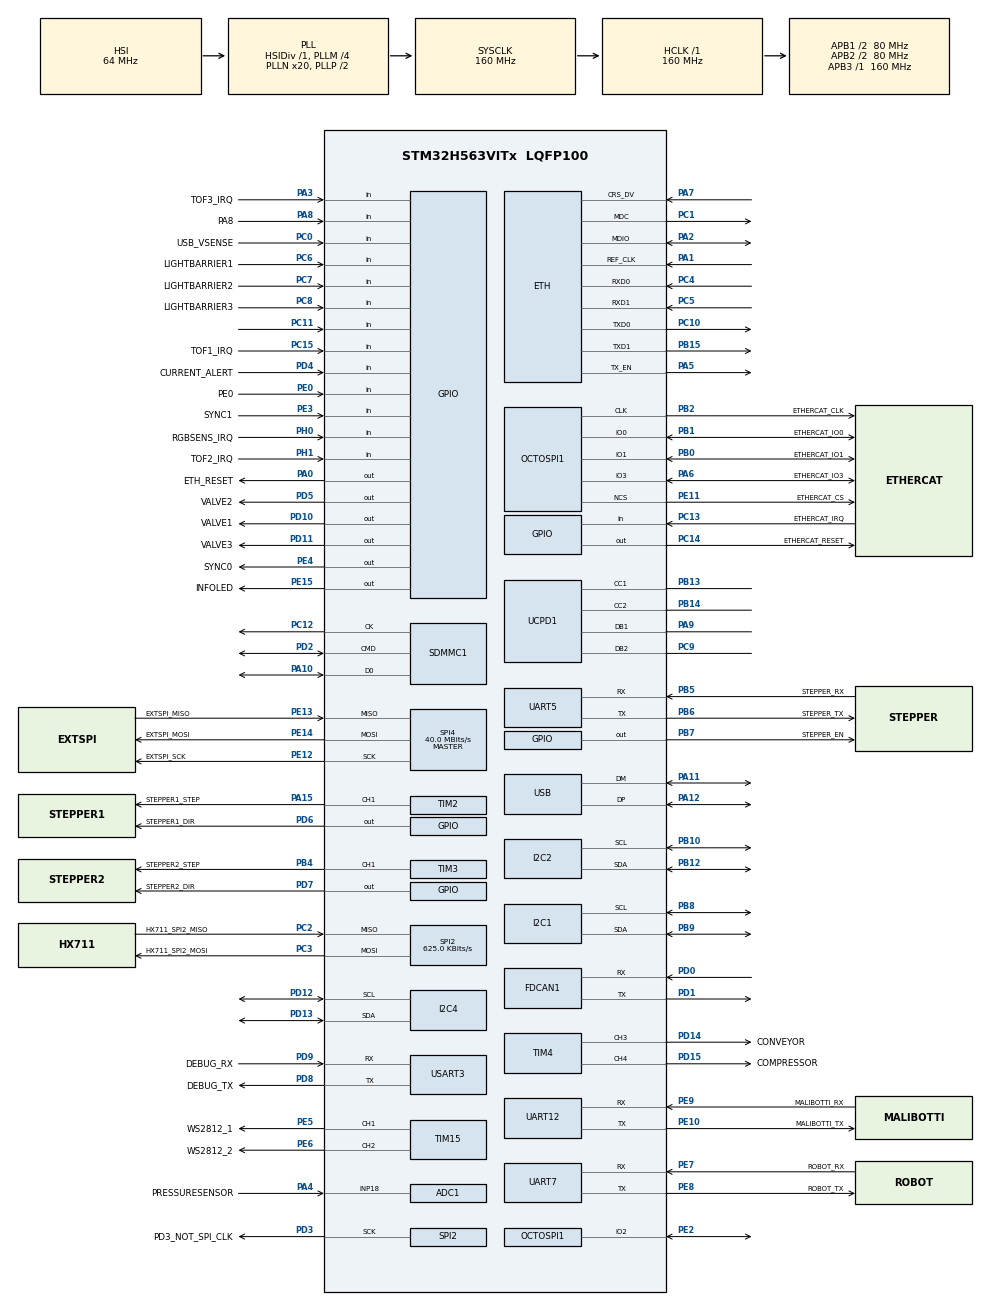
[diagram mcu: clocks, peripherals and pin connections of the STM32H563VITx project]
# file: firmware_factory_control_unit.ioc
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ADC1.Channel-0\#ChannelRegularConversion=ADC_CHANNEL_18
ADC1.ContinuousConvMode=ENABLE
ADC1.MonitoredBy-0\#ChannelRegularConversion=__NULL
ADC1.NbrOfConversionFlag=1
ADC1.OffsetNumber-0\#ChannelRegularConversion=ADC_OFFSET_NONE
ADC1.Rank-0\#ChannelRegularConversion=1
ADC1.SamplingTime-0\#ChannelRegularConversion=ADC_SAMPLETIME_2CYCLES_5
ADC1.master=1
BOOTPATH.BootPathName=LEGACY
BOOTPATH.UserSelectedBootPath=LEGACY
CORTEX_M33_NS.userName=CORTEX_M33
ETH.MediaInterface=HAL_ETH_RMII_MODE
FDCAN1.CalculateBaudRateNominal=1666666
FDCAN1.CalculateTimeBitNominal=600
FDCAN1.CalculateTimeQuantumNominal=200.0
GPDMA1.ChannelPRIV_GPDMACH0=DMA_CHANNEL_NPRIV
GPDMA1.ChannelPRIV_GPDMACH1=DMA_CHANNEL_NPRIV
GPDMA1.DESTINC_GPDMACH1=DMA_DINC_INCREMENTED
GPDMA1.DIRECTION_GPDMACH0=DMA_MEMORY_TO_PERIPH
GPDMA1.DIRECTION_GPDMACH2=DMA_MEMORY_TO_PERIPH
GPDMA1.IPHANDLE_GPDMACH0-SIMPLEREQUEST_GPDMACH0=__NULL
GPDMA1.IPHANDLE_GPDMACH1-SIMPLEREQUEST_GPDMACH1=__NULL
GPDMA1.IPHANDLE_GPDMACH2-SIMPLEREQUEST_GPDMACH2=__NULL
GPDMA1.IPHANDLE_GPDMACH3-SIMPLEREQUEST_GPDMACH3=__NULL
GPDMA1.REQUEST_GPDMACH0=GPDMA1_REQUEST_SPI2_TX
GPDMA1.REQUEST_GPDMACH1=GPDMA1_REQUEST_SPI2_RX
GPDMA1.REQUEST_GPDMACH2=GPDMA1_REQUEST_TIM15_CH1
GPDMA1.REQUEST_GPDMACH3=GPDMA1_REQUEST_TIM15_UP
GPDMA1.SRCINC_GPDMACH0=DMA_SINC_INCREMENTED
GPDMA1.SRCINC_GPDMACH2=DMA_SINC_INCREMENTED
GPDMA1.SRCINC_GPDMACH3=DMA_SINC_INCREMENTED
I2C1.Timing=0x10909CEC
I2C2.Timing=0x10909CEC
I2C4.Timing=0x30909DEC
Mcu.Family=STM32H5
Mcu.Name=STM32H563VITx
Mcu.Package=LQFP100
NVIC.ETH_IRQn=true\:5\:0\:true\:false\:true\:true\:true\:true
NVIC.ETH_WKUP_IRQn=true\:5\:0\:true\:false\:true\:true\:true\:true
NVIC.GPDMA1_Channel0_IRQn=true\:0\:0\:false\:false\:true\:false\:true\:true
NVIC.GPDMA1_Channel1_IRQn=true\:0\:0\:false\:false\:true\:false\:true\:true
NVIC.GPDMA1_Channel2_IRQn=true\:0\:0\:false\:false\:true\:false\:true\:true
NVIC.GPDMA1_Channel3_IRQn=true\:0\:0\:false\:false\:true\:false\:true\:true
NVIC.PriorityGroup=NVIC_PRIORITYGROUP_4
NVIC.SDMMC1_IRQn=true\:0\:0\:false\:false\:true\:true\:true\:true
NVIC.SPI2_IRQn=true\:5\:0\:true\:false\:true\:true\:true\:true
NVIC.UART5_IRQn=true\:5\:0\:true\:false\:true\:true\:true\:true
PA0.GPIO_Label=ETH_RESET
PA0.Signal=GPIO_Output
PA1.Mode=RMII
PA1.Signal=ETH_REF_CLK
PA10.Mode=SD_1_bit
PA10.Signal=SDMMC1_D0
PA11.Mode=Device
PA11.Signal=USB_DM
PA12.Mode=Device
PA12.Signal=USB_DP
PA13(JTMS/SWDIO).Mode=Serial_Wire
PA13(JTMS/SWDIO).Signal=DEBUG_JTMS-SWDIO
PA14(JTCK/SWCLK).Mode=Serial_Wire
PA14(JTCK/SWCLK).Signal=DEBUG_JTCK-SWCLK
PA15(JTDI).GPIO_Label=STEPPER1_STEP
PA15(JTDI).Signal=S_TIM2_CH1
PA2.Mode=RMII
PA2.Signal=ETH_MDIO
PA3.GPIO_Label=TOF3_IRQ
PA3.Signal=GPIO_Input
PA4.GPIO_Label=PRESSURESENSOR
PA4.Signal=ADCx_INP18
PA5.Mode=RMII
PA5.Signal=ETH_TX_EN
PA6.GPIO_Label=ETHERCAT_IO3
PA6.Mode=OCTOSPI1_IO[3\:0]
PA6.Signal=OCTOSPI1_IO3
PA7.Mode=RMII
PA7.Signal=ETH_CRS_DV
PA8.GPIO_Label=PA8
PA8.Signal=GPIO_Input
PA9.Mode=EnableDeadBattery
PA9.Signal=UCPD1_DB1
PB0.GPIO_Label=ETHERCAT_IO1
PB0.Mode=OCTOSPI1_IO[3\:0]
PB0.Signal=OCTOSPI1_IO1
PB1.GPIO_Label=ETHERCAT_IO0
PB1.Mode=OCTOSPI1_IO[3\:0]
PB1.Signal=OCTOSPI1_IO0
PB10.Mode=I2C
PB10.Signal=I2C2_SCL
PB12.Mode=I2C
PB12.Signal=I2C2_SDA
PB13.Mode=Sink_AllSignals
PB13.Signal=UCPD1_CC1
PB14.Mode=Sink_AllSignals
PB14.Signal=UCPD1_CC2
PB15.Mode=RMII
PB15.Signal=ETH_TXD1
PB2.GPIO_Label=ETHERCAT_CLK
PB2.Mode=quad_mode
PB2.Signal=OCTOSPI1_CLK
PB3(JTDO/TRACESWO).Signal=DEBUG_JTDO-SWO
PB4(NJTRST).GPIO_Label=STEPPER2_STEP
PB4(NJTRST).Signal=S_TIM3_CH1
PB5.GPIO_Label=STEPPER_RX
PB5.Mode=Asynchronous
PB5.Signal=UART5_RX
PB6.GPIO_Label=STEPPER_TX
PB6.Mode=Asynchronous
PB6.Signal=UART5_TX
PB7.GPIO_Label=STEPPER_EN
PB7.PinState=GPIO_PIN_SET
PB7.Signal=GPIO_Output
PB8.Mode=I2C
PB8.Signal=I2C1_SCL
PB9.Mode=I2C
PB9.Signal=I2C1_SDA
PC0.GPIO_Label=USB_VSENSE
PC0.Signal=GPIO_Input
PC1.Mode=RMII
PC1.Signal=ETH_MDC
PC10.Mode=RMII
PC10.Signal=ETH_TXD0
PC11.Signal=GPIO_Input
PC12.Mode=SD_1_bit
PC12.Signal=SDMMC1_CK
PC13.GPIO_Label=ETHERCAT_IRQ
PC13.Signal=GPIO_Input
PC14-OSC32_IN(OSC32_IN).GPIO_Label=ETHERCAT_RESET
PC14-OSC32_IN(OSC32_IN).Signal=GPIO_Output
PC15-OSC32_OUT(OSC32_OUT).GPIO_Label=TOF1_IRQ
PC15-OSC32_OUT(OSC32_OUT).Signal=GPIO_Input
PC2.GPIO_Label=HX711_SPI2_MISO
PC2.Mode=Full_Duplex_Master
PC2.Signal=SPI2_MISO
PC3.GPIO_Label=HX711_SPI2_MOSI
PC3.Mode=Full_Duplex_Master
PC3.Signal=SPI2_MOSI
PC4.Mode=RMII
PC4.Signal=ETH_RXD0
PC5.Mode=RMII
PC5.Signal=ETH_RXD1
PC6.GPIO_Label=LIGHTBARRIER1
PC6.Signal=GPIO_Input
PC7.GPIO_Label=LIGHTBARRIER2
PC7.Signal=GPIO_Input
PC8.GPIO_Label=LIGHTBARRIER3
PC8.Signal=GPIO_Input
PC9.Mode=EnableDeadBattery
PC9.Signal=UCPD1_DB2
PD0.Mode=FDCAN_Activate
PD0.Signal=FDCAN1_RX
PD1.Mode=FDCAN_Activate
PD1.Signal=FDCAN1_TX
PD10.GPIO_Label=VALVE1
PD10.Signal=GPIO_Output
PD11.GPIO_Label=VALVE3
PD11.Signal=GPIO_Output
PD12.Mode=I2C
PD12.Signal=I2C4_SCL
PD13.Mode=I2C
PD13.Signal=I2C4_SDA
PD14.GPIO_Label=CONVEYOR
PD14.Signal=S_TIM4_CH3
PD15.GPIO_Label=COMPRESSOR
PD15.Signal=S_TIM4_CH4
PD2.Mode=SD_1_bit
PD2.Signal=SDMMC1_CMD
PD3.GPIO_Label=PD3_NOT_SPI_CLK
PD3.Mode=Full_Duplex_Master
PD3.Signal=SPI2_SCK
PD4.GPIO_Label=CURRENT_ALERT
PD4.GPIO_PuPd=GPIO_PULLUP
PD4.Signal=GPIO_Input
PD5.GPIO_Label=VALVE2
PD5.Signal=GPIO_Output
PD6.GPIO_Label=STEPPER1_DIR
PD6.Signal=GPIO_Output
PD7.GPIO_Label=STEPPER2_DIR
PD7.Signal=GPIO_Output
PD8.GPIO_Label=DEBUG_TX
PD8.Mode=Asynchronous
PD8.Signal=USART3_TX
PD9.GPIO_Label=DEBUG_RX
PD9.Mode=Asynchronous
PD9.Signal=USART3_RX
PE0.GPIO_Label=PE0
PE0.Signal=GPIO_Input
PE10.GPIO_Label=MALIBOTTI_TX
PE10.Mode=Asynchronous
PE10.Signal=UART12_TX
PE11.GPIO_Label=ETHERCAT_CS
PE11.Mode=quad_mode
PE11.Signal=OCTOSPI1_NCS
PE12.GPIO_Label=EXTSPI_SCK
PE12.Mode=Full_Duplex_Master
PE12.Signal=SPI4_SCK
PE13.GPIO_Label=EXTSPI_MISO
PE13.Mode=Full_Duplex_Master
PE13.Signal=SPI4_MISO
PE14.GPIO_Label=EXTSPI_MOSI
PE14.Mode=Full_Duplex_Master
PE14.Signal=SPI4_MOSI
PE15.GPIO_Label=INFOLED
PE15.Signal=GPIO_Output
PE2.Mode=OCTOSPI1_IO[3\:0]
PE2.Signal=OCTOSPI1_IO2
PE3.GPIO_Label=SYNC1
PE3.Signal=GPIO_Input
PE4.GPIO_Label=SYNC0
PE4.Signal=GPIO_Output
PE5.GPIO_Label=WS2812_1
PE5.Signal=S_TIM15_CH1
PE6.GPIO_Label=WS2812_2
PE6.Signal=S_TIM15_CH2
PE7.GPIO_Label=ROBOT_RX
PE7.Mode=Asynchronous
PE7.Signal=UART7_RX
PE8.GPIO_Label=ROBOT_TX
PE8.Mode=Asynchronous
PE8.Signal=UART7_TX
PE9.GPIO_Label=MALIBOTTI_RX
PE9.Mode=Asynchronous
PE9.Signal=UART12_RX
PH0-OSC_IN(PH0).GPIO_Label=RGBSENS_IRQ
PH0-OSC_IN(PH0).Signal=GPIO_Input
PH1-OSC_OUT(PH1).GPIO_Label=TOF2_IRQ
PH1-OSC_OUT(PH1).Signal=GPIO_Input
ProjectManager.HeapSize=0x200
ProjectManager.StackSize=0x2000
ProjectManager.TargetToolchain=CMake
RCC.ADCFreq_Value=160000000
RCC.AHBFreq_Value=160000000
RCC.APB1CLKDivider=RCC_HCLK_DIV2
RCC.APB1Freq_Value=80000000
RCC.APB1TimFreq_Value=160000000
RCC.APB2CLKDivider=RCC_HCLK_DIV2
RCC.APB2Freq_Value=80000000
RCC.APB2TimFreq_Value=160000000
RCC.APB3Freq_Value=160000000
RCC.CSI_VALUE=4000000
RCC.CortexFreq_Value=160000000
RCC.EPOD_VALUE=64000000
RCC.FDCANClockSelection=RCC_FDCANCLKSOURCE_PLL1Q
RCC.HCLKFreq_Value=160000000
RCC.HSE_VALUE=25000000
RCC.HSI48_VALUE=48000000
RCC.HSIDiv=RCC_HSI_DIV1
RCC.HSI_VALUE=64000000
RCC.LSE_VALUE=32768
RCC.LSIRC_VALUE=32000
RCC.PLL1Q=4
RCC.PLLFRACN=0
RCC.PLLM=4
RCC.PLLN=20
RCC.PLLSourceVirtual=RCC_PLL1_SOURCE_HSI
RCC.SYSCLKFreq_VALUE=160000000
RCC.SYSCLKSource=RCC_SYSCLKSOURCE_PLLCLK
RCC.USBFreq_Value=48000000
RCC.VCOOutputFreq_Value=320000000
SH.ADCx_INP18.0=ADC1_INP18,IN18-Single-Ended
SH.S_TIM15_CH1.0=TIM15_CH1,PWM Generation1 CH1
SH.S_TIM15_CH2.0=TIM15_CH2,PWM Generation2 CH2
SH.S_TIM2_CH1.0=TIM2_CH1,Output Compare1 CH1
SH.S_TIM3_CH1.0=TIM3_CH1,Output Compare1 CH1
SH.S_TIM4_CH3.0=TIM4_CH3,PWM Generation3 CH3
SH.S_TIM4_CH4.0=TIM4_CH4,PWM Generation4 CH4
SPI2.BaudRatePrescaler=SPI_BAUDRATEPRESCALER_128
SPI2.CalculateBaudRate=625.0 KBits/s
SPI2.DataSize=SPI_DATASIZE_8BIT
SPI2.Direction=SPI_DIRECTION_2LINES
SPI2.Mode=SPI_MODE_MASTER
SPI2.VirtualType=VM_MASTER
SPI4.CalculateBaudRate=40.0 MBits/s
SPI4.Direction=SPI_DIRECTION_2LINES
SPI4.Mode=SPI_MODE_MASTER
SPI4.VirtualType=VM_MASTER
TIM15.Channel-PWM\ Generation1\ CH1=TIM_CHANNEL_1
TIM15.Channel-PWM\ Generation2\ CH2=TIM_CHANNEL_2
TIM2.Channel-Output\ Compare1\ CH1=TIM_CHANNEL_1
TIM3.Channel-Output\ Compare1\ CH1=TIM_CHANNEL_1
TIM4.Channel-PWM\ Generation3\ CH3=TIM_CHANNEL_3
TIM4.Channel-PWM\ Generation4\ CH4=TIM_CHANNEL_4
UART5.FIFOMode=FIFOMODE_ENABLE
USART3.VirtualMode-Asynchronous=VM_ASYNC
USB.VirtualMode=Device_Only
VP_BOOTPATH_VS_BOOTPATH.Mode=BP_Activate
VP_CORTEX_M33_NS_VS_Hclk.Mode=Hclk_Mode
VP_DCACHE1_VS_DCACHE.Mode=DCACHE_Activate
VP_FLASH_SIG_Activate_FlashIP.Mode=Activate_FlashIP
VP_GPDMA1_VS_GPDMACH0.Mode=SIMPLEREQUEST_GPDMACH0
VP_GPDMA1_VS_GPDMACH1.Mode=SIMPLEREQUEST_GPDMACH1
VP_GPDMA1_VS_GPDMACH2.Mode=SIMPLEREQUEST_GPDMACH2
VP_GPDMA1_VS_GPDMACH3.Mode=SIMPLEREQUEST_GPDMACH3
VP_ICACHE_VS_ICACHE.Mode=DefaultMode
VP_MEMORYMAP_VS_MEMORYMAP.Mode=CurAppReg
VP_PWR_VS_LPOM.Mode=PowerOptimisation
VP_PWR_VS_SECSignals.Mode=Security/Privilege
VP_TIM16_VS_ClockSourceINT.Mode=Enable_Timer
VP_TIM17_VS_ClockSourceINT.Mode=Enable_Timer
board=custom

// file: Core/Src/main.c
/* USER CODE BEGIN Header */
/**
  ******************************************************************************
  * @file           : main.c
  * @brief          : Main program body
  ******************************************************************************
  * @attention
  *
  * Copyright (c) 2026 STMicroelectronics.
  * All rights reserved.
  *
  * This software is licensed under terms that can be found in the LICENSE file
  * in the root directory of this software component.
  * If no LICENSE file comes with this software, it is provided AS-IS.
  *
  ******************************************************************************
  */
/* USER CODE END Header */
#include "main.h"
#include "string.h"

/* USER CODE BEGIN Includes */
#include <stdio.h>
#include "tx_api.h"
#include "generated/device_ids.hh"

void enable_dwt_cycle_counter(void); // common_stm32/common.cc
/* USER CODE END Includes */

ETH_TxPacketConfigTypeDef TxConfig;
ETH_DMADescTypeDef  DMARxDscrTab[ETH_RX_DESC_CNT]; /* Ethernet Rx DMA Descriptors */
ETH_DMADescTypeDef  DMATxDscrTab[ETH_TX_DESC_CNT]; /* Ethernet Tx DMA Descriptors */

ADC_HandleTypeDef hadc1;

DCACHE_HandleTypeDef hdcache1;

ETH_HandleTypeDef heth;

FDCAN_HandleTypeDef hfdcan1;

I2C_HandleTypeDef hi2c1;
I2C_HandleTypeDef hi2c2;
I2C_HandleTypeDef hi2c4;

XSPI_HandleTypeDef hxspi1;

SD_HandleTypeDef hsd1;

SPI_HandleTypeDef hspi2;
SPI_HandleTypeDef hspi4;
DMA_HandleTypeDef handle_GPDMA1_Channel1;
DMA_HandleTypeDef handle_GPDMA1_Channel0;

TIM_HandleTypeDef htim2;
TIM_HandleTypeDef htim3;
TIM_HandleTypeDef htim4;
TIM_HandleTypeDef htim15;
TIM_HandleTypeDef htim16;
TIM_HandleTypeDef htim17;
DMA_HandleTypeDef handle_GPDMA1_Channel3;
DMA_HandleTypeDef handle_GPDMA1_Channel2;

UART_HandleTypeDef huart5;
UART_HandleTypeDef huart7;
UART_HandleTypeDef huart12;
UART_HandleTypeDef huart3;

PCD_HandleTypeDef hpcd_USB_DRD_FS;

void SystemClock_Config(void);
static void MX_GPIO_Init(void);
static void MX_GPDMA1_Init(void);
static void MX_DCACHE1_Init(void);
static void MX_USART3_UART_Init(void);
static void MX_ETH_Init(void);
static void MX_FLASH_Init(void);
static void MX_I2C1_Init(void);
static void MX_I2C2_Init(void);
static void MX_I2C4_Init(void);
static void MX_SDMMC1_SD_Init(void);
static void MX_SPI2_Init(void);
static void MX_TIM2_Init(void);
static void MX_TIM3_Init(void);
static void MX_TIM4_Init(void);
static void MX_TIM15_Init(void);
static void MX_UART7_Init(void);
static void MX_UCPD1_Init(void);
static void MX_USB_PCD_Init(void);
static void MX_FDCAN1_Init(void);
static void MX_SPI4_Init(void);
static void MX_OCTOSPI1_Init(void);
static void MX_TIM16_Init(void);
static void MX_TIM17_Init(void);
static void MX_UART12_Init(void);
static void MX_ADC1_Init(void);
static void MX_UART5_Init(void);
static void MX_ICACHE_Init(void);

int main(void)
{

  /* USER CODE BEGIN 1 */
  // DWT-Zykluszaehler ganz am Anfang aktivieren (nicht erst in _tx_initialize_low_level(), das
  // erst mit tx_kernel_enter() weit unten laeuft) -- hal_tick_threadx.c braucht ihn schon fuer
  // HAL_Delay()/HAL_GetTick()-Aufrufe, die VOR dem ThreadX-Kernelstart passieren (z.B.
  // SystemClock_Config() und die MX_*_Init()-Timeouts) und fuer die CPU-Zeit-Statistik
  // (tx_execution_profile.c).
  // tx_initialize_low_level.S setzt dieselben Enable-Bits spaeter nochmals -- harmlos, setzt
  // CYCCNT dort nicht zurueck. Nur hier, genau einmal aufrufen (s. common.cc).
  enable_dwt_cycle_counter();
  /* USER CODE END 1 */

  /* MCU Configuration--------------------------------------------------------*/

  /* Reset of all peripherals, Initializes the Flash interface and the Systick. */
  HAL_Init();

  /* Configure the system clock */
  SystemClock_Config();

  /* Initialize all configured peripherals */
  MX_GPIO_Init();
  /* USER CODE BEGIN 2 */
  // Alle MX_*_Init() ausser MX_GPIO_Init() stehen in der .ioc auf "Do Not Generate Function
  // Call" -- hier nur, was VOR der Versorgungsspannungspruefung (App::WaitForSupplyVoltage(),
  // s. app.cc) gebraucht wird: Caches/Flash/DMA als Basis, USART3 fuers Log, I2C4 fuer den
  // INA226, UCPD1 fuer USB-PD. Alle stromhungrigen Peripherien (ETH, Stepper-UART/-Timer, SD,
  // USB-Device, ...) initialisiert erst MX_Init_PowerConsumers() unten, aufgerufen aus dem
  // App-Main-Thread, sobald >18V anliegen. MX_GPIO_Init() oben laesst STEPPER_EN (Low-aktiv)
  // HIGH und den ETH-PHY im Reset (ETH_RESET LOW) -- die Verbraucher bleiben bis dahin aus.
  MX_GPDMA1_Init();
  MX_DCACHE1_Init();
  MX_USART3_UART_Init();
  MX_FLASH_Init();
  MX_I2C4_Init();
  MX_UCPD1_Init();
  MX_ICACHE_Init();
  tx_kernel_enter();
  /* USER CODE END 2 */

  /* Infinite loop */
  while (1)
  {

  }
}

void SystemClock_Config(void)
{
  RCC_OscInitTypeDef RCC_OscInitStruct = {0};
  RCC_ClkInitTypeDef RCC_ClkInitStruct = {0};

  /** Configure the main internal regulator output voltage
  */
  __HAL_PWR_VOLTAGESCALING_CONFIG(PWR_REGULATOR_VOLTAGE_SCALE1);

  while(!__HAL_PWR_GET_FLAG(PWR_FLAG_VOSRDY)) {}

  /** Initializes the RCC Oscillators according to the specified parameters
  * in the RCC_OscInitTypeDef structure.
  */
  RCC_OscInitStruct.OscillatorType = RCC_OSCILLATORTYPE_HSI48|RCC_OSCILLATORTYPE_HSI;
  RCC_OscInitStruct.HSIState = RCC_HSI_ON;
  RCC_OscInitStruct.HSIDiv = RCC_HSI_DIV1;
  RCC_OscInitStruct.HSICalibrationValue = RCC_HSICALIBRATION_DEFAULT;
  RCC_OscInitStruct.HSI48State = RCC_HSI48_ON;
  RCC_OscInitStruct.PLL.PLLState = RCC_PLL_ON;
  RCC_OscInitStruct.PLL.PLLSource = RCC_PLL1_SOURCE_HSI;
  RCC_OscInitStruct.PLL.PLLM = 4;
  RCC_OscInitStruct.PLL.PLLN = 20;
  RCC_OscInitStruct.PLL.PLLP = 2;
  RCC_OscInitStruct.PLL.PLLQ = 4;
  RCC_OscInitStruct.PLL.PLLR = 2;
  RCC_OscInitStruct.PLL.PLLRGE = RCC_PLL1_VCIRANGE_3;
  RCC_OscInitStruct.PLL.PLLVCOSEL = RCC_PLL1_VCORANGE_WIDE;
  RCC_OscInitStruct.PLL.PLLFRACN = 0;
  if (HAL_RCC_OscConfig(&RCC_OscInitStruct) != HAL_OK)
  {
    Error_Handler();
  }

  /** Initializes the CPU, AHB and APB buses clocks
  */
  RCC_ClkInitStruct.ClockType = RCC_CLOCKTYPE_HCLK|RCC_CLOCKTYPE_SYSCLK
                              |RCC_CLOCKTYPE_PCLK1|RCC_CLOCKTYPE_PCLK2
                              |RCC_CLOCKTYPE_PCLK3;
  RCC_ClkInitStruct.SYSCLKSource = RCC_SYSCLKSOURCE_PLLCLK;
  RCC_ClkInitStruct.AHBCLKDivider = RCC_SYSCLK_DIV1;
  RCC_ClkInitStruct.APB1CLKDivider = RCC_HCLK_DIV2;
  RCC_ClkInitStruct.APB2CLKDivider = RCC_HCLK_DIV2;
  RCC_ClkInitStruct.APB3CLKDivider = RCC_HCLK_DIV1;

  if (HAL_RCC_ClockConfig(&RCC_ClkInitStruct, FLASH_LATENCY_4) != HAL_OK)
  {
    Error_Handler();
  }

  /** Configure the programming delay
  */
  __HAL_FLASH_SET_PROGRAM_DELAY(FLASH_PROGRAMMING_DELAY_2);
}

static void MX_ADC1_Init(void)
{

  ADC_ChannelConfTypeDef sConfig = {0};

  /** Common config
  */
  hadc1.Instance = ADC1;
  hadc1.Init.ClockPrescaler = ADC_CLOCK_ASYNC_DIV4;
  hadc1.Init.Resolution = ADC_RESOLUTION_12B;
  hadc1.Init.DataAlign = ADC_DATAALIGN_RIGHT;
  hadc1.Init.ScanConvMode = ADC_SCAN_DISABLE;
  hadc1.Init.EOCSelection = ADC_EOC_SINGLE_CONV;
  hadc1.Init.LowPowerAutoWait = DISABLE;
  hadc1.Init.ContinuousConvMode = ENABLE;
  hadc1.Init.NbrOfConversion = 1;
  hadc1.Init.DiscontinuousConvMode = DISABLE;
  hadc1.Init.ExternalTrigConv = ADC_SOFTWARE_START;
  hadc1.Init.ExternalTrigConvEdge = ADC_EXTERNALTRIGCONVEDGE_NONE;
  hadc1.Init.DMAContinuousRequests = DISABLE;
  hadc1.Init.SamplingMode = ADC_SAMPLING_MODE_NORMAL;
  hadc1.Init.Overrun = ADC_OVR_DATA_PRESERVED;
  hadc1.Init.OversamplingMode = DISABLE;
  if (HAL_ADC_Init(&hadc1) != HAL_OK)
  {
    Error_Handler();
  }

  /** Configure Regular Channel
  */
  sConfig.Channel = ADC_CHANNEL_18;
  sConfig.Rank = ADC_REGULAR_RANK_1;
  sConfig.SamplingTime = ADC_SAMPLETIME_2CYCLES_5;
  sConfig.SingleDiff = ADC_SINGLE_ENDED;
  sConfig.OffsetNumber = ADC_OFFSET_NONE;
  sConfig.Offset = 0;
  if (HAL_ADC_ConfigChannel(&hadc1, &sConfig) != HAL_OK)
  {
    Error_Handler();
  }

}

static void MX_DCACHE1_Init(void)
{

  hdcache1.Instance = DCACHE1;
  hdcache1.Init.ReadBurstType = DCACHE_READ_BURST_WRAP;
  if (HAL_DCACHE_Init(&hdcache1) != HAL_OK)
  {
    Error_Handler();
  }

}

static void MX_ETH_Init(void)
{

   static uint8_t MACAddr[6];

  heth.Instance = ETH;
  MACAddr[0] = 0x00;
  MACAddr[1] = 0x80;
  MACAddr[2] = 0xE1;
  MACAddr[3] = 0x00;
  MACAddr[4] = 0x00;
  MACAddr[5] = 0x00;
  heth.Init.MACAddr = &MACAddr[0];
  heth.Init.MediaInterface = HAL_ETH_RMII_MODE;
  heth.Init.TxDesc = DMATxDscrTab;
  heth.Init.RxDesc = DMARxDscrTab;
  heth.Init.RxBuffLen = 1524;

  /* USER CODE BEGIN MACADDRESS */
  // Statt der von CubeMX generierten, fuer ALLE Boards identischen MAC (00:80:E1:00:00:00,
  // s.o.) -- bei mehreren Geraeten im selben Netz sonst ARP-Kollisionen. DEVICE_ETH_MAC (Core/
  // generated/device_ids.hh, von builder/Phases/ReadHardwareIds.cs eincompiliert) ist
  // bereits pro Board aus dessen 96-Bit-Chip-Unique-ID abgeleitet -- frueher
  // (s. Commit-Historie) wurde dieselbe XOR-Faltung stattdessen bei JEDEM Boot per
  // HAL_GetUIDw0/1/2() neu berechnet, was zusaetzlich ein HAL_ICACHE_Disable()/_Enable()-Paar
  // brauchte (UID_BASE liegt im OTP-/System-Speicherbereich, nicht im regulaeren
  // Flash-Adressraum, den der ICACHE ueberwacht) -- DEVICE_ETH_MAC liegt dagegen als gewoehnliche
  // Konstante im normalen, ICACHE-sicheren Flash-Bereich, das Disable/Enable-Paar entfaellt also
  // komplett.
  memcpy(MACAddr, DEVICE_ETH_MAC, sizeof(MACAddr));
  /* USER CODE END MACADDRESS */

  if (HAL_ETH_Init(&heth) != HAL_OK)
  {
    Error_Handler();
  }

  memset(&TxConfig, 0 , sizeof(ETH_TxPacketConfigTypeDef));
  TxConfig.Attributes = ETH_TX_PACKETS_FEATURES_CSUM | ETH_TX_PACKETS_FEATURES_CRCPAD;
  TxConfig.ChecksumCtrl = ETH_CHECKSUM_IPHDR_PAYLOAD_INSERT_PHDR_CALC;
  TxConfig.CRCPadCtrl = ETH_CRC_PAD_INSERT;

}

static void MX_FDCAN1_Init(void)
{

  hfdcan1.Instance = FDCAN1;
  hfdcan1.Init.ClockDivider = FDCAN_CLOCK_DIV1;
  hfdcan1.Init.FrameFormat = FDCAN_FRAME_CLASSIC;
  hfdcan1.Init.Mode = FDCAN_MODE_NORMAL;
  hfdcan1.Init.AutoRetransmission = DISABLE;
  hfdcan1.Init.TransmitPause = DISABLE;
  hfdcan1.Init.ProtocolException = DISABLE;
  hfdcan1.Init.NominalPrescaler = 16;
  hfdcan1.Init.NominalSyncJumpWidth = 1;
  hfdcan1.Init.NominalTimeSeg1 = 1;
  hfdcan1.Init.NominalTimeSeg2 = 1;
  hfdcan1.Init.DataPrescaler = 1;
  hfdcan1.Init.DataSyncJumpWidth = 1;
  hfdcan1.Init.DataTimeSeg1 = 1;
  hfdcan1.Init.DataTimeSeg2 = 1;
  hfdcan1.Init.StdFiltersNbr = 0;
  hfdcan1.Init.ExtFiltersNbr = 0;
  hfdcan1.Init.TxFifoQueueMode = FDCAN_TX_FIFO_OPERATION;
  if (HAL_FDCAN_Init(&hfdcan1) != HAL_OK)
  {
    Error_Handler();
  }

}

static void MX_FLASH_Init(void)
{

  if (HAL_FLASH_Unlock() != HAL_OK)
  {
    Error_Handler();
  }
  if (HAL_FLASH_Lock() != HAL_OK)
  {
    Error_Handler();
  }

}

static void MX_GPDMA1_Init(void)
{

  /* Peripheral clock enable */
  __HAL_RCC_GPDMA1_CLK_ENABLE();

  /* GPDMA1 interrupt Init */
    HAL_NVIC_SetPriority(GPDMA1_Channel0_IRQn, 0, 0);
    HAL_NVIC_EnableIRQ(GPDMA1_Channel0_IRQn);
    HAL_NVIC_SetPriority(GPDMA1_Channel1_IRQn, 0, 0);
    HAL_NVIC_EnableIRQ(GPDMA1_Channel1_IRQn);
    HAL_NVIC_SetPriority(GPDMA1_Channel2_IRQn, 0, 0);
    HAL_NVIC_EnableIRQ(GPDMA1_Channel2_IRQn);
    HAL_NVIC_SetPriority(GPDMA1_Channel3_IRQn, 0, 0);
    HAL_NVIC_EnableIRQ(GPDMA1_Channel3_IRQn);

}

static void MX_I2C1_Init(void)
{

  hi2c1.Instance = I2C1;
  hi2c1.Init.Timing = 0x10909CEC;
  hi2c1.Init.OwnAddress1 = 0;
  hi2c1.Init.AddressingMode = I2C_ADDRESSINGMODE_7BIT;
  hi2c1.Init.DualAddressMode = I2C_DUALADDRESS_DISABLE;
  hi2c1.Init.OwnAddress2 = 0;
  hi2c1.Init.OwnAddress2Masks = I2C_OA2_NOMASK;
  hi2c1.Init.GeneralCallMode = I2C_GENERALCALL_DISABLE;
  hi2c1.Init.NoStretchMode = I2C_NOSTRETCH_DISABLE;
  if (HAL_I2C_Init(&hi2c1) != HAL_OK)
  {
    Error_Handler();
  }

  /** Configure Analogue filter
  */
  if (HAL_I2CEx_ConfigAnalogFilter(&hi2c1, I2C_ANALOGFILTER_ENABLE) != HAL_OK)
  {
    Error_Handler();
  }

  /** Configure Digital filter
  */
  if (HAL_I2CEx_ConfigDigitalFilter(&hi2c1, 0) != HAL_OK)
  {
    Error_Handler();
  }

}

static void MX_I2C2_Init(void)
{

  hi2c2.Instance = I2C2;
  hi2c2.Init.Timing = 0x10909CEC;
  hi2c2.Init.OwnAddress1 = 0;
  hi2c2.Init.AddressingMode = I2C_ADDRESSINGMODE_7BIT;
  hi2c2.Init.DualAddressMode = I2C_DUALADDRESS_DISABLE;
  hi2c2.Init.OwnAddress2 = 0;
  hi2c2.Init.OwnAddress2Masks = I2C_OA2_NOMASK;
  hi2c2.Init.GeneralCallMode = I2C_GENERALCALL_DISABLE;
  hi2c2.Init.NoStretchMode = I2C_NOSTRETCH_DISABLE;
  if (HAL_I2C_Init(&hi2c2) != HAL_OK)
  {
    Error_Handler();
  }

  /** Configure Analogue filter
  */
  if (HAL_I2CEx_ConfigAnalogFilter(&hi2c2, I2C_ANALOGFILTER_ENABLE) != HAL_OK)
  {
    Error_Handler();
  }

  /** Configure Digital filter
  */
  if (HAL_I2CEx_ConfigDigitalFilter(&hi2c2, 0) != HAL_OK)
  {
    Error_Handler();
  }

}

static void MX_I2C4_Init(void)
{

  hi2c4.Instance = I2C4;
  hi2c4.Init.Timing = 0x30909DEC;
  hi2c4.Init.OwnAddress1 = 0;
  hi2c4.Init.AddressingMode = I2C_ADDRESSINGMODE_7BIT;
  hi2c4.Init.DualAddressMode = I2C_DUALADDRESS_DISABLE;
  hi2c4.Init.OwnAddress2 = 0;
  hi2c4.Init.OwnAddress2Masks = I2C_OA2_NOMASK;
  hi2c4.Init.GeneralCallMode = I2C_GENERALCALL_DISABLE;
  hi2c4.Init.NoStretchMode = I2C_NOSTRETCH_DISABLE;
  if (HAL_I2C_Init(&hi2c4) != HAL_OK)
  {
    Error_Handler();
  }

  /** Configure Analogue filter
  */
  if (HAL_I2CEx_ConfigAnalogFilter(&hi2c4, I2C_ANALOGFILTER_ENABLE) != HAL_OK)
  {
    Error_Handler();
  }

  /** Configure Digital filter
  */
  if (HAL_I2CEx_ConfigDigitalFilter(&hi2c4, 0) != HAL_OK)
  {
    Error_Handler();
  }

}

static void MX_ICACHE_Init(void)
{

  /** Enable instruction cache (default 2-ways set associative cache)
  */
  if (HAL_ICACHE_Enable() != HAL_OK)
  {
    Error_Handler();
  }

}

static void MX_OCTOSPI1_Init(void)
{

  /* OCTOSPI1 parameter configuration*/
  hxspi1.Instance = OCTOSPI1;
  hxspi1.Init.FifoThresholdByte = 1;
  hxspi1.Init.MemoryMode = HAL_XSPI_SINGLE_MEM;
  hxspi1.Init.MemoryType = HAL_XSPI_MEMTYPE_MICRON;
  hxspi1.Init.MemorySize = HAL_XSPI_SIZE_16B;
  hxspi1.Init.ChipSelectHighTimeCycle = 1;
  hxspi1.Init.FreeRunningClock = HAL_XSPI_FREERUNCLK_DISABLE;
  hxspi1.Init.ClockMode = HAL_XSPI_CLOCK_MODE_0;
  hxspi1.Init.WrapSize = HAL_XSPI_WRAP_NOT_SUPPORTED;
  hxspi1.Init.ClockPrescaler = 0;
  hxspi1.Init.SampleShifting = HAL_XSPI_SAMPLE_SHIFT_NONE;
  hxspi1.Init.DelayHoldQuarterCycle = HAL_XSPI_DHQC_DISABLE;
  hxspi1.Init.ChipSelectBoundary = HAL_XSPI_BONDARYOF_NONE;
  hxspi1.Init.DelayBlockBypass = HAL_XSPI_DELAY_BLOCK_BYPASS;
  hxspi1.Init.Refresh = 0;
  if (HAL_XSPI_Init(&hxspi1) != HAL_OK)
  {
    Error_Handler();
  }

}

static void MX_SDMMC1_SD_Init(void)
{

  /* USER CODE BEGIN SDMMC1_Init 0 */
  hsd1.Instance = SDMMC1;
  hsd1.Init.ClockEdge = SDMMC_CLOCK_EDGE_RISING;
  hsd1.Init.ClockPowerSave = SDMMC_CLOCK_POWER_SAVE_DISABLE;
  hsd1.Init.BusWide = SDMMC_BUS_WIDE_1B;
  hsd1.Init.HardwareFlowControl = SDMMC_HARDWARE_FLOW_CONTROL_DISABLE;
  hsd1.Init.ClockDiv = 0;
  HAL_SD_Init(&hsd1);
  return; // siehe USER CODE BEGIN SDMMC1_Init 2 unten
  /* USER CODE END SDMMC1_Init 0 */

  hsd1.Instance = SDMMC1;
  hsd1.Init.ClockEdge = SDMMC_CLOCK_EDGE_RISING;
  hsd1.Init.ClockPowerSave = SDMMC_CLOCK_POWER_SAVE_DISABLE;
  hsd1.Init.BusWide = SDMMC_BUS_WIDE_1B;
  hsd1.Init.HardwareFlowControl = SDMMC_HARDWARE_FLOW_CONTROL_DISABLE;
  hsd1.Init.ClockDiv = 0;
  if (HAL_SD_Init(&hsd1) != HAL_OK)
  {
    Error_Handler();
  }
  /* USER CODE BEGIN SDMMC1_Init 2 */
  // Absichtlich KEIN Error_Handler() bei HAL_SD_Init()-Fehlschlag: die microSD-Karte ist
  // optionale Hardware (aktuell nur fuer FileX/den NetX-HTTP-Server reserviert, der die
  // eigentliche Modbus-UI laengst aus dem Flash statt von der SD-Karte liefert, s.
  // webserver.cpp) -- eine nicht gesteckte Karte darf den kompletten Boot (Netzwerk/Modbus/
  // alles) nicht blockieren. HAL_SD_Init() liefert bei fehlender Karte einen begrenzten
  // Timeout-Fehler zurueck (kein Haenger), hsd1 bleibt dann einfach im nicht initialisierten
  // Zustand -- fx_media_open() in net_setup.cpp faengt das spaeter ebenfalls nicht-fatal ab.
  //
  // Achtung: HAL_SD_Init() ist generierter CubeMX-Code (ausserhalb dieses USER-CODE-Blocks) --
  // dieser Fixup (Entfernen des urspruenglichen "if(...!= HAL_OK) Error_Handler();") muss nach
  // jeder CubeMX-Neuerzeugung manuell wiederholt werden.
  HAL_SD_Init(&hsd1);
  /* USER CODE END SDMMC1_Init 2 */

}

static void MX_SPI2_Init(void)
{

  /* SPI2 parameter configuration*/
  hspi2.Instance = SPI2;
  hspi2.Init.Mode = SPI_MODE_MASTER;
  hspi2.Init.Direction = SPI_DIRECTION_2LINES;
  hspi2.Init.DataSize = SPI_DATASIZE_8BIT;
  hspi2.Init.CLKPolarity = SPI_POLARITY_LOW;
  hspi2.Init.CLKPhase = SPI_PHASE_1EDGE;
  hspi2.Init.NSS = SPI_NSS_SOFT;
  hspi2.Init.BaudRatePrescaler = SPI_BAUDRATEPRESCALER_128;
  hspi2.Init.FirstBit = SPI_FIRSTBIT_MSB;
  hspi2.Init.TIMode = SPI_TIMODE_DISABLE;
  hspi2.Init.CRCCalculation = SPI_CRCCALCULATION_DISABLE;
  hspi2.Init.CRCPolynomial = 0x7;
  hspi2.Init.NSSPMode = SPI_NSS_PULSE_ENABLE;
  hspi2.Init.NSSPolarity = SPI_NSS_POLARITY_LOW;
  hspi2.Init.FifoThreshold = SPI_FIFO_THRESHOLD_01DATA;
  hspi2.Init.MasterSSIdleness = SPI_MASTER_SS_IDLENESS_00CYCLE;
  hspi2.Init.MasterInterDataIdleness = SPI_MASTER_INTERDATA_IDLENESS_00CYCLE;
  hspi2.Init.MasterReceiverAutoSusp = SPI_MASTER_RX_AUTOSUSP_DISABLE;
  hspi2.Init.MasterKeepIOState = SPI_MASTER_KEEP_IO_STATE_DISABLE;
  hspi2.Init.IOSwap = SPI_IO_SWAP_DISABLE;
  hspi2.Init.ReadyMasterManagement = SPI_RDY_MASTER_MANAGEMENT_INTERNALLY;
  hspi2.Init.ReadyPolarity = SPI_RDY_POLARITY_HIGH;
  if (HAL_SPI_Init(&hspi2) != HAL_OK)
  {
    Error_Handler();
  }
  /* USER CODE BEGIN SPI2_Init 2 */
  // In CubeMX ist fuer SPI2 kein NVIC-Interrupt angehakt, CubeMX generiert daher weder diesen
  // Aufruf noch den SPI2_IRQHandler (s. stm32h5xx_it.c, USER CODE BEGIN 1). hx711.hh braucht
  // ihn zwingend: HAL_SPI_TransmitReceive_DMA() schliesst die Transaktion erst ueber das
  // SPI-eigene EOT-Interrupt ab, nicht schon ueber die DMA-Completion-IRQs allein. TODO: in
  // CubeMX dauerhaft nachpflegen (SPI2 -> NVIC Settings -> Global Interrupt), sonst geht das
  // beim naechsten "Generate Code" wieder verloren.
  HAL_NVIC_SetPriority(SPI2_IRQn, 5, 0);
  HAL_NVIC_EnableIRQ(SPI2_IRQn);
  /* USER CODE END SPI2_Init 2 */

}

static void MX_SPI4_Init(void)
{

  /* SPI4 parameter configuration*/
  hspi4.Instance = SPI4;
  hspi4.Init.Mode = SPI_MODE_MASTER;
  hspi4.Init.Direction = SPI_DIRECTION_2LINES;
  hspi4.Init.DataSize = SPI_DATASIZE_4BIT;
  hspi4.Init.CLKPolarity = SPI_POLARITY_LOW;
  hspi4.Init.CLKPhase = SPI_PHASE_1EDGE;
  hspi4.Init.NSS = SPI_NSS_SOFT;
  hspi4.Init.BaudRatePrescaler = SPI_BAUDRATEPRESCALER_2;
  hspi4.Init.FirstBit = SPI_FIRSTBIT_MSB;
  hspi4.Init.TIMode = SPI_TIMODE_DISABLE;
  hspi4.Init.CRCCalculation = SPI_CRCCALCULATION_DISABLE;
  hspi4.Init.CRCPolynomial = 0x7;
  hspi4.Init.NSSPMode = SPI_NSS_PULSE_ENABLE;
  hspi4.Init.NSSPolarity = SPI_NSS_POLARITY_LOW;
  hspi4.Init.FifoThreshold = SPI_FIFO_THRESHOLD_01DATA;
  hspi4.Init.MasterSSIdleness = SPI_MASTER_SS_IDLENESS_00CYCLE;
  hspi4.Init.MasterInterDataIdleness = SPI_MASTER_INTERDATA_IDLENESS_00CYCLE;
  hspi4.Init.MasterReceiverAutoSusp = SPI_MASTER_RX_AUTOSUSP_DISABLE;
  hspi4.Init.MasterKeepIOState = SPI_MASTER_KEEP_IO_STATE_DISABLE;
  hspi4.Init.IOSwap = SPI_IO_SWAP_DISABLE;
  hspi4.Init.ReadyMasterManagement = SPI_RDY_MASTER_MANAGEMENT_INTERNALLY;
  hspi4.Init.ReadyPolarity = SPI_RDY_POLARITY_HIGH;
  if (HAL_SPI_Init(&hspi4) != HAL_OK)
  {
    Error_Handler();
  }

}

static void MX_TIM2_Init(void)
{

  TIM_MasterConfigTypeDef sMasterConfig = {0};
  TIM_OC_InitTypeDef sConfigOC = {0};

  htim2.Instance = TIM2;
  htim2.Init.Prescaler = 0;
  htim2.Init.CounterMode = TIM_COUNTERMODE_UP;
  htim2.Init.Period = 4294967295;
  htim2.Init.ClockDivision = TIM_CLOCKDIVISION_DIV1;
  htim2.Init.AutoReloadPreload = TIM_AUTORELOAD_PRELOAD_DISABLE;
  if (HAL_TIM_OC_Init(&htim2) != HAL_OK)
  {
    Error_Handler();
  }
  sMasterConfig.MasterOutputTrigger = TIM_TRGO_RESET;
  sMasterConfig.MasterSlaveMode = TIM_MASTERSLAVEMODE_DISABLE;
  if (HAL_TIMEx_MasterConfigSynchronization(&htim2, &sMasterConfig) != HAL_OK)
  {
    Error_Handler();
  }
  sConfigOC.OCMode = TIM_OCMODE_TIMING;
  sConfigOC.Pulse = 0;
  sConfigOC.OCPolarity = TIM_OCPOLARITY_HIGH;
  sConfigOC.OCFastMode = TIM_OCFAST_DISABLE;
  if (HAL_TIM_OC_ConfigChannel(&htim2, &sConfigOC, TIM_CHANNEL_1) != HAL_OK)
  {
    Error_Handler();
  }
  HAL_TIM_MspPostInit(&htim2);

}

static void MX_TIM3_Init(void)
{

  TIM_MasterConfigTypeDef sMasterConfig = {0};
  TIM_OC_InitTypeDef sConfigOC = {0};

  htim3.Instance = TIM3;
  htim3.Init.Prescaler = 0;
  htim3.Init.CounterMode = TIM_COUNTERMODE_UP;
  htim3.Init.Period = 65535;
  htim3.Init.ClockDivision = TIM_CLOCKDIVISION_DIV1;
  htim3.Init.AutoReloadPreload = TIM_AUTORELOAD_PRELOAD_DISABLE;
  if (HAL_TIM_OC_Init(&htim3) != HAL_OK)
  {
    Error_Handler();
  }
  sMasterConfig.MasterOutputTrigger = TIM_TRGO_RESET;
  sMasterConfig.MasterSlaveMode = TIM_MASTERSLAVEMODE_DISABLE;
  if (HAL_TIMEx_MasterConfigSynchronization(&htim3, &sMasterConfig) != HAL_OK)
  {
    Error_Handler();
  }
  sConfigOC.OCMode = TIM_OCMODE_TIMING;
  sConfigOC.Pulse = 0;
  sConfigOC.OCPolarity = TIM_OCPOLARITY_HIGH;
  sConfigOC.OCFastMode = TIM_OCFAST_DISABLE;
  if (HAL_TIM_OC_ConfigChannel(&htim3, &sConfigOC, TIM_CHANNEL_1) != HAL_OK)
  {
    Error_Handler();
  }
  HAL_TIM_MspPostInit(&htim3);

}

static void MX_TIM4_Init(void)
{

  TIM_MasterConfigTypeDef sMasterConfig = {0};
  TIM_OC_InitTypeDef sConfigOC = {0};

  htim4.Instance = TIM4;
  htim4.Init.Prescaler = 0;
  htim4.Init.CounterMode = TIM_COUNTERMODE_UP;
  htim4.Init.Period = 65535;
  htim4.Init.ClockDivision = TIM_CLOCKDIVISION_DIV1;
  htim4.Init.AutoReloadPreload = TIM_AUTORELOAD_PRELOAD_DISABLE;
  if (HAL_TIM_PWM_Init(&htim4) != HAL_OK)
  {
    Error_Handler();
  }
  sMasterConfig.MasterOutputTrigger = TIM_TRGO_RESET;
  sMasterConfig.MasterSlaveMode = TIM_MASTERSLAVEMODE_DISABLE;
  if (HAL_TIMEx_MasterConfigSynchronization(&htim4, &sMasterConfig) != HAL_OK)
  {
    Error_Handler();
  }
  sConfigOC.OCMode = TIM_OCMODE_PWM1;
  sConfigOC.Pulse = 0;
  sConfigOC.OCPolarity = TIM_OCPOLARITY_HIGH;
  sConfigOC.OCFastMode = TIM_OCFAST_DISABLE;
  if (HAL_TIM_PWM_ConfigChannel(&htim4, &sConfigOC, TIM_CHANNEL_3) != HAL_OK)
  {
    Error_Handler();
  }
  if (HAL_TIM_PWM_ConfigChannel(&htim4, &sConfigOC, TIM_CHANNEL_4) != HAL_OK)
  {
    Error_Handler();
  }
  HAL_TIM_MspPostInit(&htim4);

}

static void MX_TIM15_Init(void)
{

  TIM_MasterConfigTypeDef sMasterConfig = {0};
  TIM_OC_InitTypeDef sConfigOC = {0};
  TIM_BreakDeadTimeConfigTypeDef sBreakDeadTimeConfig = {0};

  htim15.Instance = TIM15;
  htim15.Init.Prescaler = 0;
  htim15.Init.CounterMode = TIM_COUNTERMODE_UP;
  htim15.Init.Period = 65535;
  htim15.Init.ClockDivision = TIM_CLOCKDIVISION_DIV1;
  htim15.Init.RepetitionCounter = 0;
  htim15.Init.AutoReloadPreload = TIM_AUTORELOAD_PRELOAD_DISABLE;
  if (HAL_TIM_PWM_Init(&htim15) != HAL_OK)
  {
    Error_Handler();
  }
  sMasterConfig.MasterOutputTrigger = TIM_TRGO_RESET;
  sMasterConfig.MasterSlaveMode = TIM_MASTERSLAVEMODE_DISABLE;
  if (HAL_TIMEx_MasterConfigSynchronization(&htim15, &sMasterConfig) != HAL_OK)
  {
    Error_Handler();
  }
  sConfigOC.OCMode = TIM_OCMODE_PWM1;
  sConfigOC.Pulse = 0;
  sConfigOC.OCPolarity = TIM_OCPOLARITY_HIGH;
  sConfigOC.OCNPolarity = TIM_OCNPOLARITY_HIGH;
  sConfigOC.OCFastMode = TIM_OCFAST_DISABLE;
  sConfigOC.OCIdleState = TIM_OCIDLESTATE_RESET;
  sConfigOC.OCNIdleState = TIM_OCNIDLESTATE_RESET;
  if (HAL_TIM_PWM_ConfigChannel(&htim15, &sConfigOC, TIM_CHANNEL_1) != HAL_OK)
  {
    Error_Handler();
  }
  if (HAL_TIM_PWM_ConfigChannel(&htim15, &sConfigOC, TIM_CHANNEL_2) != HAL_OK)
  {
    Error_Handler();
  }
  sBreakDeadTimeConfig.OffStateRunMode = TIM_OSSR_DISABLE;
  sBreakDeadTimeConfig.OffStateIDLEMode = TIM_OSSI_DISABLE;
  sBreakDeadTimeConfig.LockLevel = TIM_LOCKLEVEL_OFF;
  sBreakDeadTimeConfig.DeadTime = 0;
  sBreakDeadTimeConfig.BreakState = TIM_BREAK_DISABLE;
  sBreakDeadTimeConfig.BreakPolarity = TIM_BREAKPOLARITY_HIGH;
  sBreakDeadTimeConfig.BreakFilter = 0;
  sBreakDeadTimeConfig.AutomaticOutput = TIM_AUTOMATICOUTPUT_DISABLE;
  if (HAL_TIMEx_ConfigBreakDeadTime(&htim15, &sBreakDeadTimeConfig) != HAL_OK)
  {
    Error_Handler();
  }
  HAL_TIM_MspPostInit(&htim15);

}

static void MX_TIM16_Init(void)
{

  htim16.Instance = TIM16;
  htim16.Init.Prescaler = 0;
  htim16.Init.CounterMode = TIM_COUNTERMODE_UP;
  htim16.Init.Period = 65535;
  htim16.Init.ClockDivision = TIM_CLOCKDIVISION_DIV1;
  htim16.Init.RepetitionCounter = 0;
  htim16.Init.AutoReloadPreload = TIM_AUTORELOAD_PRELOAD_DISABLE;
  if (HAL_TIM_Base_Init(&htim16) != HAL_OK)
  {
    Error_Handler();
  }

}

static void MX_TIM17_Init(void)
{

  htim17.Instance = TIM17;
  htim17.Init.Prescaler = 0;
  htim17.Init.CounterMode = TIM_COUNTERMODE_UP;
  htim17.Init.Period = 65535;
  htim17.Init.ClockDivision = TIM_CLOCKDIVISION_DIV1;
  htim17.Init.RepetitionCounter = 0;
  htim17.Init.AutoReloadPreload = TIM_AUTORELOAD_PRELOAD_DISABLE;
  if (HAL_TIM_Base_Init(&htim17) != HAL_OK)
  {
    Error_Handler();
  }

}

static void MX_UART5_Init(void)
{

  huart5.Instance = UART5;
  huart5.Init.BaudRate = 115200;
  huart5.Init.WordLength = UART_WORDLENGTH_8B;
  huart5.Init.StopBits = UART_STOPBITS_1;
  huart5.Init.Parity = UART_PARITY_NONE;
  huart5.Init.Mode = UART_MODE_TX_RX;
  huart5.Init.HwFlowCtl = UART_HWCONTROL_NONE;
  huart5.Init.OverSampling = UART_OVERSAMPLING_16;
  huart5.Init.OneBitSampling = UART_ONE_BIT_SAMPLE_DISABLE;
  huart5.Init.ClockPrescaler = UART_PRESCALER_DIV1;
  huart5.AdvancedInit.AdvFeatureInit = UART_ADVFEATURE_NO_INIT;
  if (HAL_UART_Init(&huart5) != HAL_OK)
  {
    Error_Handler();
  }
  if (HAL_UARTEx_SetTxFifoThreshold(&huart5, UART_TXFIFO_THRESHOLD_1_8) != HAL_OK)
  {
    Error_Handler();
  }
  if (HAL_UARTEx_SetRxFifoThreshold(&huart5, UART_RXFIFO_THRESHOLD_1_8) != HAL_OK)
  {
    Error_Handler();
  }
  if (HAL_UARTEx_EnableFifoMode(&huart5) != HAL_OK)
  {
    Error_Handler();
  }
  /* USER CODE BEGIN UART5_Init 2 */
  // FIFO bewusst aktiviert (CubeMX-Default fuer dieses Board war deaktiviert, s. History) --
  // ohne FIFO hat UART5 nur ein 1-Byte-Schieberegister: bei 115200 Baud muss die RXNE-ISR
  // dann JEDES Byte innerhalb von ~87us bedienen, sonst ueberschreibt das naechste Byte
  // (Overrun) unbemerkt das vorherige. Aus dem bare-metal main() (vor tx_kernel_enter()) war
  // das nie ein Problem, aus dem ThreadX-IO-Thread heraus (TMC2209-UART-Reads waehrend des
  // Homings, s. stepper.hh) schon: dort konkurriert die ISR-Bedienung mit Ethernet/TIM6/
  // TIM16/TIM17 & Co., und gelegentliche Jitter > 87us reichten fuer stille Frame-Korruption
  // (TX/RX-Timeout ohne erkennbaren Fehler). Der 8-Byte-FIFO gibt dafuer deutlich mehr Puffer.
  // WICHTIG: in CubeMX (.ioc) muss UART5 -> Advanced Parameters -> FIFO Mode ebenfalls auf
  // "Enable" gesetzt werden, sonst geht diese Aenderung beim naechsten "Generate Code" verloren.
  /* USER CODE END UART5_Init 2 */

}

static void MX_UART7_Init(void)
{

  huart7.Instance = UART7;
  huart7.Init.BaudRate = 115200;
  huart7.Init.WordLength = UART_WORDLENGTH_8B;
  huart7.Init.StopBits = UART_STOPBITS_1;
  huart7.Init.Parity = UART_PARITY_NONE;
  huart7.Init.Mode = UART_MODE_TX_RX;
  huart7.Init.HwFlowCtl = UART_HWCONTROL_NONE;
  huart7.Init.OverSampling = UART_OVERSAMPLING_16;
  huart7.Init.OneBitSampling = UART_ONE_BIT_SAMPLE_DISABLE;
  huart7.Init.ClockPrescaler = UART_PRESCALER_DIV1;
  huart7.AdvancedInit.AdvFeatureInit = UART_ADVFEATURE_NO_INIT;
  if (HAL_UART_Init(&huart7) != HAL_OK)
  {
    Error_Handler();
  }
  if (HAL_UARTEx_SetTxFifoThreshold(&huart7, UART_TXFIFO_THRESHOLD_1_8) != HAL_OK)
  {
    Error_Handler();
  }
  if (HAL_UARTEx_SetRxFifoThreshold(&huart7, UART_RXFIFO_THRESHOLD_1_8) != HAL_OK)
  {
    Error_Handler();
  }
  if (HAL_UARTEx_DisableFifoMode(&huart7) != HAL_OK)
  {
    Error_Handler();
  }

}

static void MX_UART12_Init(void)
{

  huart12.Instance = UART12;
  huart12.Init.BaudRate = 115200;
  huart12.Init.WordLength = UART_WORDLENGTH_8B;
  huart12.Init.StopBits = UART_STOPBITS_1;
  huart12.Init.Parity = UART_PARITY_NONE;
  huart12.Init.Mode = UART_MODE_TX_RX;
  huart12.Init.HwFlowCtl = UART_HWCONTROL_NONE;
  huart12.Init.OverSampling = UART_OVERSAMPLING_16;
  huart12.Init.OneBitSampling = UART_ONE_BIT_SAMPLE_DISABLE;
  huart12.Init.ClockPrescaler = UART_PRESCALER_DIV1;
  huart12.AdvancedInit.AdvFeatureInit = UART_ADVFEATURE_NO_INIT;
  if (HAL_UART_Init(&huart12) != HAL_OK)
  {
    Error_Handler();
  }
  if (HAL_UARTEx_SetTxFifoThreshold(&huart12, UART_TXFIFO_THRESHOLD_1_8) != HAL_OK)
  {
    Error_Handler();
  }
  if (HAL_UARTEx_SetRxFifoThreshold(&huart12, UART_RXFIFO_THRESHOLD_1_8) != HAL_OK)
  {
    Error_Handler();
  }
  if (HAL_UARTEx_DisableFifoMode(&huart12) != HAL_OK)
  {
    Error_Handler();
  }

}

static void MX_USART3_UART_Init(void)
{

  huart3.Instance = USART3;
  huart3.Init.BaudRate = 115200;
  huart3.Init.WordLength = UART_WORDLENGTH_8B;
  huart3.Init.StopBits = UART_STOPBITS_1;
  huart3.Init.Parity = UART_PARITY_NONE;
  huart3.Init.Mode = UART_MODE_TX_RX;
  huart3.Init.HwFlowCtl = UART_HWCONTROL_NONE;
  huart3.Init.OverSampling = UART_OVERSAMPLING_16;
  huart3.Init.OneBitSampling = UART_ONE_BIT_SAMPLE_DISABLE;
  huart3.Init.ClockPrescaler = UART_PRESCALER_DIV1;
  huart3.AdvancedInit.AdvFeatureInit = UART_ADVFEATURE_NO_INIT;
  if (HAL_UART_Init(&huart3) != HAL_OK)
  {
    Error_Handler();
  }
  if (HAL_UARTEx_SetTxFifoThreshold(&huart3, UART_TXFIFO_THRESHOLD_1_8) != HAL_OK)
  {
    Error_Handler();
  }
  if (HAL_UARTEx_SetRxFifoThreshold(&huart3, UART_RXFIFO_THRESHOLD_1_8) != HAL_OK)
  {
    Error_Handler();
  }
  if (HAL_UARTEx_DisableFifoMode(&huart3) != HAL_OK)
  {
    Error_Handler();
  }

}

static void MX_UCPD1_Init(void)
{

  LL_GPIO_InitTypeDef GPIO_InitStruct = {0};

  /* Peripheral clock enable */
  LL_APB1_GRP2_EnableClock(LL_APB1_GRP2_PERIPH_UCPD1);

  LL_AHB2_GRP1_EnableClock(LL_AHB2_GRP1_PERIPH_GPIOB);
  /**UCPD1 GPIO Configuration
  PB13   ------> UCPD1_CC1
  PB14   ------> UCPD1_CC2
  */
  GPIO_InitStruct.Pin = LL_GPIO_PIN_13|LL_GPIO_PIN_14;
  GPIO_InitStruct.Mode = LL_GPIO_MODE_ANALOG;
  GPIO_InitStruct.Pull = LL_GPIO_PULL_NO;
  LL_GPIO_Init(GPIOB, &GPIO_InitStruct);

}

static void MX_USB_PCD_Init(void)
{

  hpcd_USB_DRD_FS.Instance = USB_DRD_FS;
  hpcd_USB_DRD_FS.Init.dev_endpoints = 8;
  hpcd_USB_DRD_FS.Init.speed = USBD_FS_SPEED;
  hpcd_USB_DRD_FS.Init.phy_itface = PCD_PHY_EMBEDDED;
  hpcd_USB_DRD_FS.Init.Sof_enable = DISABLE;
  hpcd_USB_DRD_FS.Init.low_power_enable = DISABLE;
  hpcd_USB_DRD_FS.Init.lpm_enable = DISABLE;
  hpcd_USB_DRD_FS.Init.battery_charging_enable = DISABLE;
  hpcd_USB_DRD_FS.Init.vbus_sensing_enable = DISABLE;
  hpcd_USB_DRD_FS.Init.bulk_doublebuffer_enable = DISABLE;
  hpcd_USB_DRD_FS.Init.iso_singlebuffer_enable = DISABLE;
  if (HAL_PCD_Init(&hpcd_USB_DRD_FS) != HAL_OK)
  {
    Error_Handler();
  }
  /* USER CODE BEGIN USB_Init 2 */
  // Der USB_DRD_FS-Interrupt (NVIC-Freischaltung, Prioritaet, ISR) wird bewusst NICHT von
  // CubeMX verwaltet (im .ioc kein NVIC-Haekchen fuer USB_DRD_FS_IRQn) -- diesmal NICHT, weil
  // USBX' ux_dcd_stm32-Treiber die Peripherie exklusiv besaesse (im Gegenteil: er ist
  // HAL_PCD-basiert und erwartet den STANDARD HAL_PCD_IRQHandler()-Ablauf, s.
  // USB_DRD_FS_IRQHandler() in usbd_device.c), sondern damit die Freischaltung garantiert erst
  // NACH ux_dcd_stm32_initialize()/der USBX-Klassen-Registrierung passiert (s.
  // usbd_device_setup()) -- vorher koennte ein Interrupt auf noch nicht initialisierten
  // USBX-Systemzustand treffen. HAL_PCD_Init() hier (oben) laeuft dagegen unbedingt und lange
  // vor usbd_device_setup() (das erst aus einem ThreadX-Thread heraus laufen kann) -- unkritisch,
  // da HAL_PCD_Init() selbst laut Kommentar in ux_dcd_stm32_initialize.c keine Interrupts ausloest,
  // solange die NVIC-Freischaltung (s.o.) noch aussteht. Handler-Funktion, Prioritaet und
  // Lifecycle (HAL_PCD_Start()/_Stop() statt TinyUSBs tud_connect()/_disconnect()) liegen
  // vollstaendig in usbd_device.c.
  /* USER CODE END USB_Init 2 */

}

static void MX_GPIO_Init(void)
{
  GPIO_InitTypeDef GPIO_InitStruct = {0};

  /* GPIO Ports Clock Enable */
  __HAL_RCC_GPIOE_CLK_ENABLE();
  __HAL_RCC_GPIOC_CLK_ENABLE();
  __HAL_RCC_GPIOH_CLK_ENABLE();
  __HAL_RCC_GPIOA_CLK_ENABLE();
  __HAL_RCC_GPIOB_CLK_ENABLE();
  __HAL_RCC_GPIOD_CLK_ENABLE();

  /*Configure GPIO pin Output Level */
  HAL_GPIO_WritePin(GPIOE, SYNC0_Pin|INFOLED_Pin, GPIO_PIN_RESET);

  /*Configure GPIO pin Output Level */
  HAL_GPIO_WritePin(ETHERCAT_RESET_GPIO_Port, ETHERCAT_RESET_Pin, GPIO_PIN_RESET);

  /*Configure GPIO pin Output Level */
  HAL_GPIO_WritePin(ETH_RESET_GPIO_Port, ETH_RESET_Pin, GPIO_PIN_RESET);

  /*Configure GPIO pin Output Level */
  HAL_GPIO_WritePin(GPIOD, VALVE1_Pin|VALVE3_Pin|VALVE2_Pin|STEPPER1_DIR_Pin
                          |STEPPER2_DIR_Pin, GPIO_PIN_RESET);

  /*Configure GPIO pin Output Level */
  HAL_GPIO_WritePin(STEPPER_EN_GPIO_Port, STEPPER_EN_Pin, GPIO_PIN_SET);

  /*Configure GPIO pins : SYNC1_Pin PE0_Pin */
  GPIO_InitStruct.Pin = SYNC1_Pin|PE0_Pin;
  GPIO_InitStruct.Mode = GPIO_MODE_INPUT;
  GPIO_InitStruct.Pull = GPIO_NOPULL;
  HAL_GPIO_Init(GPIOE, &GPIO_InitStruct);

  /*Configure GPIO pins : SYNC0_Pin INFOLED_Pin */
  GPIO_InitStruct.Pin = SYNC0_Pin|INFOLED_Pin;
  GPIO_InitStruct.Mode = GPIO_MODE_OUTPUT_PP;
  GPIO_InitStruct.Pull = GPIO_NOPULL;
  GPIO_InitStruct.Speed = GPIO_SPEED_FREQ_LOW;
  HAL_GPIO_Init(GPIOE, &GPIO_InitStruct);

  /*Configure GPIO pins : ETHERCAT_IRQ_Pin TOF1_IRQ_Pin USB_VSENSE_Pin LIGHTBARRIER1_Pin
                           LIGHTBARRIER2_Pin LIGHTBARRIER3_Pin PC11 */
  GPIO_InitStruct.Pin = ETHERCAT_IRQ_Pin|TOF1_IRQ_Pin|USB_VSENSE_Pin|LIGHTBARRIER1_Pin
                          |LIGHTBARRIER2_Pin|LIGHTBARRIER3_Pin|GPIO_PIN_11;
  GPIO_InitStruct.Mode = GPIO_MODE_INPUT;
  GPIO_InitStruct.Pull = GPIO_NOPULL;
  HAL_GPIO_Init(GPIOC, &GPIO_InitStruct);

  /*Configure GPIO pin : ETHERCAT_RESET_Pin */
  GPIO_InitStruct.Pin = ETHERCAT_RESET_Pin;
  GPIO_InitStruct.Mode = GPIO_MODE_OUTPUT_PP;
  GPIO_InitStruct.Pull = GPIO_NOPULL;
  GPIO_InitStruct.Speed = GPIO_SPEED_FREQ_LOW;
  HAL_GPIO_Init(ETHERCAT_RESET_GPIO_Port, &GPIO_InitStruct);

  /*Configure GPIO pins : RGBSENS_IRQ_Pin TOF2_IRQ_Pin */
  GPIO_InitStruct.Pin = RGBSENS_IRQ_Pin|TOF2_IRQ_Pin;
  GPIO_InitStruct.Mode = GPIO_MODE_INPUT;
  GPIO_InitStruct.Pull = GPIO_NOPULL;
  HAL_GPIO_Init(GPIOH, &GPIO_InitStruct);

  /*Configure GPIO pin : ETH_RESET_Pin */
  GPIO_InitStruct.Pin = ETH_RESET_Pin;
  GPIO_InitStruct.Mode = GPIO_MODE_OUTPUT_PP;
  GPIO_InitStruct.Pull = GPIO_NOPULL;
  GPIO_InitStruct.Speed = GPIO_SPEED_FREQ_LOW;
  HAL_GPIO_Init(ETH_RESET_GPIO_Port, &GPIO_InitStruct);

  /*Configure GPIO pins : TOF3_IRQ_Pin PA8_Pin */
  GPIO_InitStruct.Pin = TOF3_IRQ_Pin|PA8_Pin;
  GPIO_InitStruct.Mode = GPIO_MODE_INPUT;
  GPIO_InitStruct.Pull = GPIO_NOPULL;
  HAL_GPIO_Init(GPIOA, &GPIO_InitStruct);

  /*Configure GPIO pins : VALVE1_Pin VALVE3_Pin VALVE2_Pin STEPPER1_DIR_Pin
                           STEPPER2_DIR_Pin */
  GPIO_InitStruct.Pin = VALVE1_Pin|VALVE3_Pin|VALVE2_Pin|STEPPER1_DIR_Pin
                          |STEPPER2_DIR_Pin;
  GPIO_InitStruct.Mode = GPIO_MODE_OUTPUT_PP;
  GPIO_InitStruct.Pull = GPIO_NOPULL;
  GPIO_InitStruct.Speed = GPIO_SPEED_FREQ_LOW;
  HAL_GPIO_Init(GPIOD, &GPIO_InitStruct);

  /*Configure GPIO pin : CURRENT_ALERT_Pin */
  GPIO_InitStruct.Pin = CURRENT_ALERT_Pin;
  GPIO_InitStruct.Mode = GPIO_MODE_INPUT;
  GPIO_InitStruct.Pull = GPIO_PULLUP;
  HAL_GPIO_Init(CURRENT_ALERT_GPIO_Port, &GPIO_InitStruct);

  /*Configure GPIO pin : STEPPER_EN_Pin */
  GPIO_InitStruct.Pin = STEPPER_EN_Pin;
  GPIO_InitStruct.Mode = GPIO_MODE_OUTPUT_PP;
  GPIO_InitStruct.Pull = GPIO_NOPULL;
  GPIO_InitStruct.Speed = GPIO_SPEED_FREQ_LOW;
  HAL_GPIO_Init(STEPPER_EN_GPIO_Port, &GPIO_InitStruct);

  /* USER CODE BEGIN MX_GPIO_Init_2 */
#ifdef BOARD_NUCLEO_H563ZI
  // Test-Rig-Ersatzsignale (s. main.h) -- GPIOB/GPIOC-Takt ist oben bereits aktiviert.
  /*Configure GPIO pin : USERBUTTON_Pin (B1) */
  GPIO_InitStruct.Pin = USERBUTTON_Pin;
  GPIO_InitStruct.Mode = GPIO_MODE_INPUT;
  GPIO_InitStruct.Pull = GPIO_NOPULL;
  HAL_GPIO_Init(USERBUTTON_GPIO_Port, &GPIO_InitStruct);

  /*Configure GPIO pin : USERLED_Pin (LD1) */
  HAL_GPIO_WritePin(USERLED_GPIO_Port, USERLED_Pin, GPIO_PIN_RESET);
  GPIO_InitStruct.Pin = USERLED_Pin;
  GPIO_InitStruct.Mode = GPIO_MODE_OUTPUT_PP;
  GPIO_InitStruct.Pull = GPIO_NOPULL;
  GPIO_InitStruct.Speed = GPIO_SPEED_FREQ_LOW;
  HAL_GPIO_Init(USERLED_GPIO_Port, &GPIO_InitStruct);
#endif
  /* USER CODE END MX_GPIO_Init_2 */
}

/* USER CODE BEGIN 4 */
// Gegenstueck zu den fruehen MX_*_Init()-Aufrufen in main() (USER CODE 2): alle restlichen
// Peripherien in der urspruenglich von CubeMX generierten Reihenfolge. Hier statt in einer
// anderen Datei, weil die MX_*_Init()-Funktionen static sind (Visibility in der .ioc).
void MX_Init_PowerConsumers(void)
{
  MX_ETH_Init();
  MX_I2C1_Init();
  MX_I2C2_Init();
  MX_SDMMC1_SD_Init();
  MX_SPI2_Init();
  MX_TIM2_Init();
  MX_TIM3_Init();
  MX_TIM4_Init();
  MX_TIM15_Init();
  MX_UART7_Init();
  MX_USB_PCD_Init();
  MX_FDCAN1_Init();
  MX_SPI4_Init();
  MX_OCTOSPI1_Init();
  MX_TIM16_Init();
  MX_TIM17_Init();
  MX_UART12_Init();
  MX_ADC1_Init();
  MX_UART5_Init();
}
/* USER CODE END 4 */

void Error_Handler(void)
{
  /* USER CODE BEGIN Error_Handler_Debug */
  /* User can add his own implementation to report the HAL error return state */
  __disable_irq();
  HAL_UART_Transmit(&huart3, (uint8_t *)"\r\nError: HAL error occurred\r\n", (uint16_t)strlen("\r\nError: HAL error occurred\r\n"), HAL_MAX_DELAY);
  while (1)
  {
  }
  /* USER CODE END Error_Handler_Debug */
}
